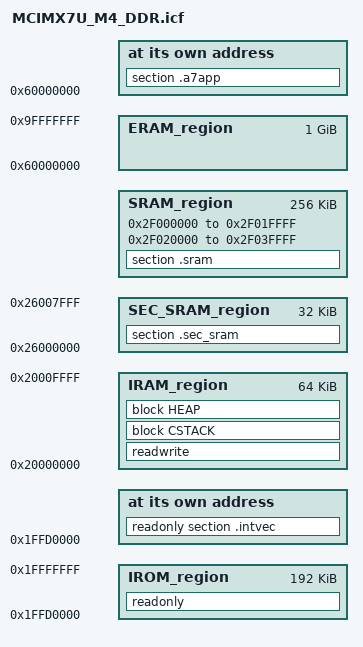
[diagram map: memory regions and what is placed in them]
/*###ICF### Section handled by ICF editor, don't touch! ****/
/*-Editor annotation file-*/
/* IcfEditorFile="$TOOLKIT_DIR$\config\ide\IcfEditor\cortex_v1_1.xml" */
/*-Specials-*/
define symbol __ICFEDIT_intvec_start__ = 0x1FFD0000;
/*-Memory Regions-*/
define symbol __ICFEDIT_region_IROM1_start__ = 0x1FFD0000;
define symbol __ICFEDIT_region_IROM1_end__   = 0x1FFFFFFF;
define symbol __ICFEDIT_region_IROM2_start__ = 0x0;
define symbol __ICFEDIT_region_IROM2_end__   = 0x0;
define symbol __ICFEDIT_region_EROM1_start__ = 0x0;
define symbol __ICFEDIT_region_EROM1_end__   = 0x0;
define symbol __ICFEDIT_region_EROM2_start__ = 0x0;
define symbol __ICFEDIT_region_EROM2_end__   = 0x0;
define symbol __ICFEDIT_region_EROM3_start__ = 0x0;
define symbol __ICFEDIT_region_EROM3_end__   = 0x0;
define symbol __ICFEDIT_region_IRAM1_start__ = 0x20000000;
define symbol __ICFEDIT_region_IRAM1_end__   = 0x2000FFFF;
define symbol __ICFEDIT_region_IRAM2_start__ = 0x0;
define symbol __ICFEDIT_region_IRAM2_end__   = 0x0;
define symbol __ICFEDIT_region_ERAM1_start__ = 0x60000000;
define symbol __ICFEDIT_region_ERAM1_end__   = 0x9FFFFFFF;
define symbol __ICFEDIT_region_ERAM2_start__ = 0x0;
define symbol __ICFEDIT_region_ERAM2_end__   = 0x0;
define symbol __ICFEDIT_region_ERAM3_start__ = 0x0;
define symbol __ICFEDIT_region_ERAM3_end__   = 0x0;
/*-Sizes-*/
define symbol __ICFEDIT_size_cstack__ = 0x400;
define symbol __ICFEDIT_size_heap__   = 0x800;
/**** End of ICF editor section. ###ICF###*/

/* SRAM0 */
define symbol SRAM0_start__      = 0x2F000000;
define symbol SRAM0_end__        = 0x2F01FFFF;

/* SRAM1 */
define symbol SRAM1_start__      = 0x2F020000;
define symbol SRAM1_end__        = 0x2F03FFFF;

/* 32K Secure SRAM */
define symbol SEC_SRAM_start__   = 0x26000000;
define symbol SEC_SRAM_end__     = 0x26007FFF;

define symbol __code_start_a7__  = __ICFEDIT_region_ERAM1_start__;

define memory mem with size = 4G;
define region IROM_region     =   mem:[from __ICFEDIT_region_IROM1_start__ to __ICFEDIT_region_IROM1_end__]
                                | mem:[from __ICFEDIT_region_IROM2_start__ to __ICFEDIT_region_IROM2_end__];
define region EROM_region     =   mem:[from __ICFEDIT_region_EROM1_start__ to __ICFEDIT_region_EROM1_end__]
                                | mem:[from __ICFEDIT_region_EROM2_start__ to __ICFEDIT_region_EROM2_end__]
                                | mem:[from __ICFEDIT_region_EROM3_start__ to __ICFEDIT_region_EROM3_end__];
define region IRAM_region     =   mem:[from __ICFEDIT_region_IRAM1_start__ to __ICFEDIT_region_IRAM1_end__]
                                | mem:[from __ICFEDIT_region_IRAM2_start__ to __ICFEDIT_region_IRAM2_end__];
define region ERAM_region     =   mem:[from __ICFEDIT_region_ERAM1_start__ to __ICFEDIT_region_ERAM1_end__]
                                | mem:[from __ICFEDIT_region_ERAM2_start__ to __ICFEDIT_region_ERAM2_end__]
                                | mem:[from __ICFEDIT_region_ERAM3_start__ to __ICFEDIT_region_ERAM3_end__];

define region SRAM_region     =   mem:[from SRAM0_start__ to SRAM0_end__]
                                | mem:[from SRAM1_start__ to SRAM1_end__];

define region SEC_SRAM_region =   mem:[from SEC_SRAM_start__ to SEC_SRAM_end__];

define block CSTACK    with alignment = 8, size = __ICFEDIT_size_cstack__   { };
define block HEAP      with alignment = 8, size = __ICFEDIT_size_heap__     { };

do not initialize  { section .noinit };
initialize by copy { readwrite };
if (isdefinedsymbol(__USE_DLIB_PERTHREAD))
{
  // Required in a multi-threaded application
  initialize by copy with packing = none { section __DLIB_PERTHREAD };
}

initialize by copy with packing = auto { section .a7app };

place at address mem:__ICFEDIT_intvec_start__ { readonly section .intvec };

place in IROM_region   { readonly };
place in EROM_region   { readonly section application_specific_ro };
place in IRAM_region   { readwrite, block CSTACK, block HEAP };
place in ERAM_region   { };

place in SRAM_region     { section .sram     };
place in SEC_SRAM_region { section .sec_sram };

place at address mem:__code_start_a7__ { section .a7app };
